# target register map
Vendor: Vango; Series: TARGET; File version: 1.0
CPU: CM0 r0p0, little endian, no MPU, no FPU, 2 interrupt priority bits
Registers are 32-bit, read-write, reset 0x0 unless marked. A register's access mark holds for its fields unless they carry their own. Offsets are from the block's base; [hi:lo] are bit positions; {n}, {i} and the like mark numbered series.

## RTC — The RTC controller is used to control time calculation and RTC auto calibration function.
Base 0x40014800
0x00 SEC reset not defined — RTC second register
  [6:0] SEC — RTC_SEC, 0~59.
0x04 MIN reset not defined — RTC minute register
  [6:0] MIN — RTC_MIN, 0~59.
0x08 HOUR reset not defined — RTC hour register
  [5:0] HOUR — RTC_HOUR, 0~23.
0x0C DAY reset not defined — RTC day register
  [5:0] DAY — RTC_DAY, 1~31.
0x10 WEEK reset not defined — RTC week register
  [2:0] WEEK — RTC_WEEK, 0~6.
0x14 MON reset not defined — RTC mon register
  [4:0] MON — RTC_MON, 1~12.
0x18 YEAR reset not defined — RTC year register
  [7:0] YEAR — RTC_YEAR, 00~99.
0x1C TIME reset not defined — RTC accurate second/millisecond register
  [21:0] TIME — This register is used to control the accurate second/millisecond function
0x20 WKUSEC — RTC wake-up second register.
  [5:0] WKUSEC — This register is used to control the multi-second wake-up function.
0x24 WKUMIN — RTC wake-up minute register
  [5:0] WKUMIN — This register is used to control the multi-minute wake-up function.
0x28 WKUHOUR — RTC wake-up hour register
  [4:0] WKUHOUR — This register is used to control the multi-hour wake-up function.
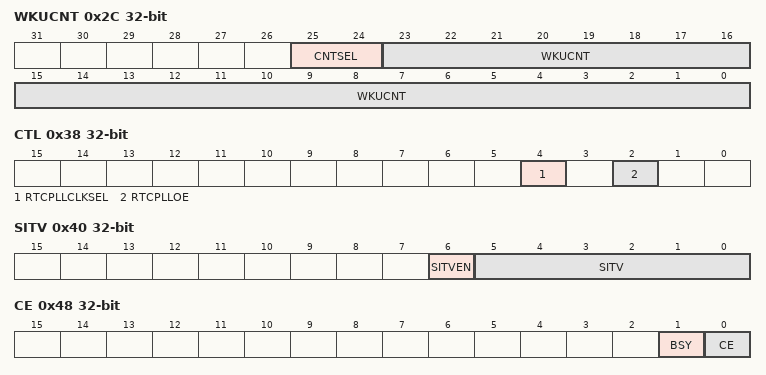
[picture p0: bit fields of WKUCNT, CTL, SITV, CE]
0x2C WKUCNT — RTC wake-up counter register
  [25:24] CNTSEL — This is register is used to set the counter clock of WKUCNT.
  [23:0] WKUCNT — This register is used to control the 32K counter wake-up function.
0x30 CAL reset not defined — RTC calibration register
  [13:0] CAL — RTC 32768 calibration register.
0x34 DIV — RTC calibration register
  [25:0] RTCDIV — This register is used to configurates RTCPLLDIV output frequency.
0x38 CTL — RTC PLL divider control register.
  [4] RTCPLLCLKSEL — RTC_PLLDIV clock select.
  [2] RTCPLLOE — RTCPLL Divider output enable.
0x3C ITV — RTC wake-up interval control
  [2:0] ITV — This register is used to control wake-up and interrupt interval of RTC.
    0=One_Second; 1=One_Minute; 2=One_Hour; 3=One_Day; 4=Every_500ms; 5=Every_250ms; 6=Every_125ms; 7=Every_62_5ms
0x40 SITV — RTC wake-up second interval control
  [6] SITVEN — Multi Second interval enable register.
  [5:0] SITV — Multi second wake-up interval control register.
0x44 PWD — RTC password control register.
  [0] PWDEN ro — This register is used to protect the RTC_CE port accessible.
0x48 CE — RTC write enable control register.
  [1] BSY ro — This flag is used to indicated the RTC update procedure or RTC read procedure is ongoing.
  [0] CE ro — This register is used to unlock the access to RTC register.
0x4C LOAD ro reset not defined — RTC read enable control register
  [31:0] LOAD — This register is used to let RTC engine read data from RTC core.
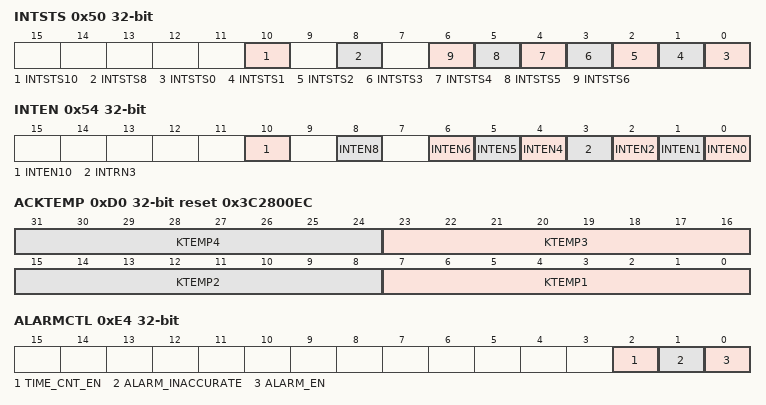
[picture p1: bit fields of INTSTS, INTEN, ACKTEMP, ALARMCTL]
0x50 INTSTS — RTC interrupt status control register
  [10] INTSTS10 write-1-clears — Interrupt status alarm.
  [8] INTSTS8 write-1-clears — Interrupt status 8.
  [n] INTSTS{n} write-1-clears (n=0..6) — Interrupt status {n}.
0x54 INTEN — RTC interrupt enable control register
  [10] INTEN10 — Interrupt enable alarm.
  [8] INTEN8 — Interrupt enable 8.
  [6] INTEN6 — Interrupt enable 6.
  [5] INTEN5 — Interrupt enable 5.
  [4] INTEN4 — Interrupt enable 4.
  [3] INTRN3 — Interrupt enable 3.
  [2] INTEN2 — Interrupt enable 2.
  [1] INTEN1 — Interrupt enable 1.
  [0] INTEN0 — Interrupt enable 0.
0x58 PSCA — RTC clock pre-scaler control register.
  [1:0] PSCA — This register is used to control the RTC clock pre-scaler.
    0=No_pre_scaler; 1=0_25_pre_scaler
0x84 ACTI reset 0x1800 — RTC auto-calibration center temperature control register.
  [13:0] ACTI — Auto-calibration Ti control register.
0x88 ACF200 reset 0x640000 — RTC auto-calibration 200*frequency control register.
  [25:0] F200 — Auto-calibration F200 control register.
0x90 ACP0 — RTC parameter P0 register.
  [15:0] P0 — The P0 register is used for temperature test.
0x94 ACP1 — RTC parameter P1 register.
  [15:0] P1 — The P1 register is used for temperature test.
0x98 ACP2 — RTC parameter P2 register.
  [31:0] P2 — The P2 register is used for temperature test.
0x9C ACP3 ro — RTC parameter P3 register.
  [31:0] P3 — The P3 register is used for frquency adjustment.
0xA0 ACP4 — RTC parameter P4 register.
  [15:0] P4 — The P4 register is the crystal temperature offset.
0xA4 ACP5 — RTC parameter P5 register.
  [15:0] P5 — The P5 register is used for RTC adjustment.
0xA8 ACP6 — RTC parameter P6 register.
  [15:0] P6 — The P6 register is used for RTC_DIV calibration.
0xAC ACP7 — RTC parameter P7 register.
  [15:0] P7 — The P7 register is used for frquency adjustment.
{0xB0+4i} ACK[{i}] (i=0..4) — RTC auto-calibration parameter Kx control register.
  [15:0] K — The registers are used for auto-calibration.
0xCC WKUCNTR ro — This register is used to represent the current WKUCNT value.
  [23:0] WKUCNTR
0xD0 ACKTEMP reset 0x3C2800EC — RTC auto-calibration k temperature section control register.
  [8n-1:8n-8] KTEMP{n} (n=1..4) — This register is used to control the section {n} temperature.
0xD4 ALARMTIME — RTC alarm accurate second/millisecond.
  [21:0] ALARMTIME — This register is used to control the accurate second and millisecond alarm function.
0xD8 ALARMSEC — RTC alarm inaccurate second
  [6:0] ALARMSEC — This register is used to control the inaccurate second alarm function
0xDC ALARMMIN — RTC alarm minute
  [6:0] ALARMMIN — This register is used to control the minute alarm function
0xE0 ALARMHOUR — RTC alarm hour
  [5:0] ALARMHOUR — This register is used to control the hour alarm function
0xE4 ALARMCTL — RTC alarm control
  [2] TIME_CNT_EN — This register is used to control alarm time counter enable.
  [1] ALARM_INACCURATE — This register is used to control alarm function accurate or not.
  [0] ALARM_EN — This register is used to control the alarm function enable.
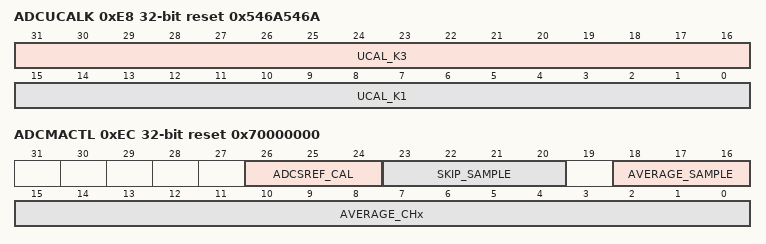
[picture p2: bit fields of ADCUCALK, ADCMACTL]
0xE8 ADCUCALK reset 0x546A546A — RTC ADC Ucal K coefficients
  [31:16] UCAL_K3, [15:0] UCAL_K1
0xEC ADCMACTL reset 0x70000000 — RTC ADC control
  [26:24] ADCSREF_CAL — ADC ADCSREF used in calibration
  [23:20] SKIP_SAMPLE — CIC output skip control register.
  [18:16] AVERAGE_SAMPLE — Moving average sample count.
    0=2_samples; 1=4_samples; 2=8_samples; 3=16_samples; 4=32_samples; 5=64_samples
  [15:0] AVERAGE_CHx — Moving average enable for a channel. BITx control Channelx. x=0~15.
0xF0 ADCDTCTL reset 0x80000000 — RTC ADC data control
  [31:30] ENDED_IN2ADC_CONVERT — Sig/diff ended data processing mode.
